AUTOSAR XML (schema 4-2-2)
package /STELLANTIS/EPT/ASWCs
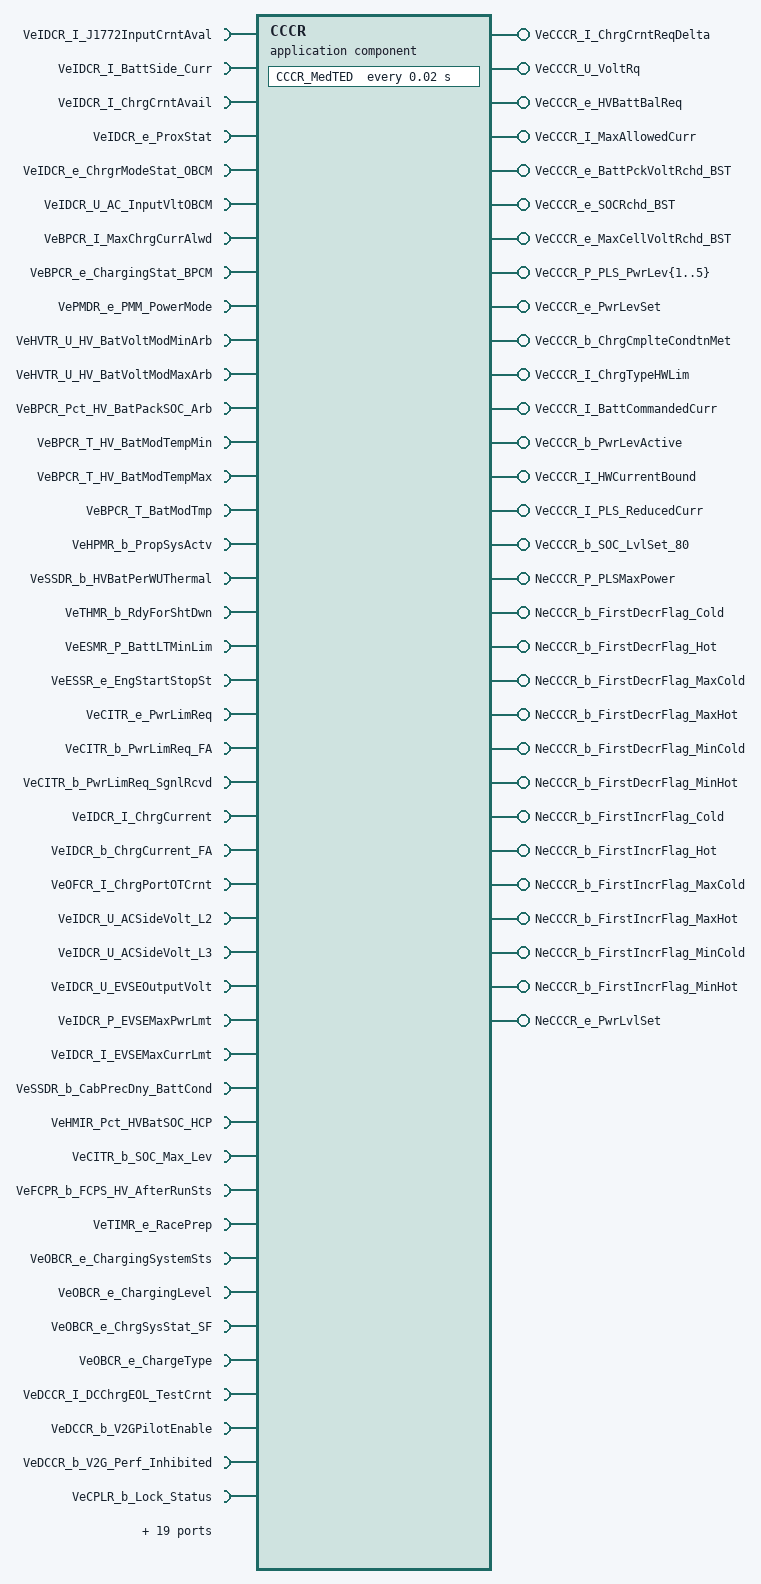
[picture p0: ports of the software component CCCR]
  application sw component type CCCR
    49 x require port:
      VeIDCR_I_J1772InputCrntAval: variation-point={short-label=vpVeIDCR_I_J1772InputCrntAval, sw-syscond=1}, nonqueued-receiver-com-spec{data-element=Value, init-value=0}, required-interface=VeIDCR_I_J1772InputCrntAval
      VeIDCR_I_BattSide_Curr: variation-point={short-label=vpVeIDCR_I_BattSide_Curr, sw-syscond=1}, nonqueued-receiver-com-spec{data-element=Value, init-value=0}, required-interface=VeIDCR_I_BattSide_Curr
      VeIDCR_I_ChrgCrntAvail: variation-point={short-label=vpVeIDCR_I_ChrgCrntAvail, sw-syscond=1}, nonqueued-receiver-com-spec{data-element=Value, init-value=0}, required-interface=VeIDCR_I_ChrgCrntAvail
      VeIDCR_e_ProxStat: variation-point={short-label=vpVeIDCR_e_ProxStat, sw-syscond=1}, nonqueued-receiver-com-spec{data-element=Value, init-value=CeOBCR_e_ProxLo_OBCM}, required-interface=VeIDCR_e_ProxStat
      VeIDCR_e_ChrgrModeStat_OBCM: variation-point={short-label=vpVeIDCR_e_ChrgrModeStat_OBCM, sw-syscond=1}, nonqueued-receiver-com-spec{data-element=Value, init-value=CeOBCR_e_Idle_OBCM}, required-interface=VeIDCR_e_ChrgrModeStat_OBCM
      VeIDCR_U_AC_InputVltOBCM: variation-point={short-label=vpVeIDCR_U_AC_InputVltOBCM, sw-syscond=1}, nonqueued-receiver-com-spec{data-element=Value, init-value=0}, required-interface=VeIDCR_U_AC_InputVltOBCM
      VeBPCR_I_MaxChrgCurrAlwd: variation-point={short-label=vpVeBPCR_I_MaxChrgCurrAlwd, sw-syscond=1}, nonqueued-receiver-com-spec{data-element=Value, init-value=0}, required-interface=VeBPCR_I_MaxChrgCurrAlwd
      VeBPCR_e_ChargingStat_BPCM: variation-point={short-label=vpVeBPCR_e_ChargingStat_BPCM, sw-syscond=1}, nonqueued-receiver-com-spec{data-element=Value, init-value=CeOBCR_e_BattNotReady}, required-interface=VeBPCR_e_ChargingStat_BPCM
      VePMDR_e_PMM_PowerMode: variation-point={short-label=vpVePMDR_e_PMM_PowerMode, sw-syscond=1}, nonqueued-receiver-com-spec{data-element=Value, init-value=CePMDR_e_PowerMode_Off}, required-interface=VePMDR_e_PMM_PowerMode
      VeHVTR_U_HV_BatVoltModMinArb: variation-point={short-label=vpVeHVTR_U_HV_BatVoltModMinArb, sw-syscond=1}, nonqueued-receiver-com-spec{data-element=Value, init-value=0}, required-interface=VeHVTR_U_HV_BatVoltModMinArb
      VeHVTR_U_HV_BatVoltModMaxArb: variation-point={short-label=vpVeHVTR_U_HV_BatVoltModMaxArb, sw-syscond=1}, nonqueued-receiver-com-spec{data-element=Value, init-value=0}, required-interface=VeHVTR_U_HV_BatVoltModMaxArb
      VeBPCR_Pct_HV_BatPackSOC_Arb: variation-point={short-label=vpVeBPCR_Pct_HV_BatPackSOC_Arb, sw-syscond=1}, nonqueued-receiver-com-spec{data-element=Value, init-value=0}, required-interface=VeBPCR_Pct_HV_BatPackSOC_Arb
      VeBPCR_T_HV_BatModTempMin: variation-point={short-label=vpVeBPCR_T_HV_BatModTempMin, sw-syscond=1}, nonqueued-receiver-com-spec{data-element=Value, init-value=0}, required-interface=VeBPCR_T_HV_BatModTempMin
      VeBPCR_T_HV_BatModTempMax: variation-point={short-label=vpVeBPCR_T_HV_BatModTempMax, sw-syscond=1}, nonqueued-receiver-com-spec{data-element=Value, init-value=0}, required-interface=VeBPCR_T_HV_BatModTempMax
      VeBPCR_T_BatModTmp: variation-point={short-label=vpVeBPCR_T_BatModTmp, sw-syscond=1}, nonqueued-receiver-com-spec{data-element=Value, init-value=0}, required-interface=VeBPCR_T_BatModTmp
      VeHPMR_b_PropSysActv: variation-point={short-label=vpVeHPMR_b_PropSysActv, sw-syscond=1}, nonqueued-receiver-com-spec{data-element=Value, init-value=0}, required-interface=VeHPMR_b_PropSysActv
      VeSSDR_b_HVBatPerWUThermal: variation-point={short-label=vpVeSSDR_b_HVBatPerWUThermal, sw-syscond=1}, nonqueued-receiver-com-spec{data-element=Value, init-value=0}, required-interface=VeSSDR_b_HVBatPerWUThermal
      VeTHMR_b_RdyForShtDwn: variation-point={short-label=vpVeTHMR_b_RdyForShtDwn, sw-syscond=1}, nonqueued-receiver-com-spec{data-element=Value, init-value=0}, required-interface=VeTHMR_b_RdyForShtDwn
      VeESMR_P_BattLTMinLim: variation-point={short-label=vpVeESMR_P_BattLTMinLim, sw-syscond=1}, nonqueued-receiver-com-spec{data-element=Value, init-value=0}, required-interface=VeESMR_P_BattLTMinLim
      VeESSR_e_EngStartStopSt: variation-point={short-label=vpVeESSR_e_EngStartStopSt, sw-syscond=1}, nonqueued-receiver-com-spec{data-element=Value, init-value=CeESSR_e_EngOff}, required-interface=VeESSR_e_EngStartStopSt
      VeCITR_e_PwrLimReq: variation-point={short-label=vpVeCITR_e_PwrLimReq, sw-syscond=1}, nonqueued-receiver-com-spec{data-element=Value, init-value=CeOBCR_e_PwrLimReq_SNA}, required-interface=VeCITR_e_PwrLimReq
      VeCITR_b_PwrLimReq_FA: variation-point={short-label=vpVeCITR_b_PwrLimReq_FA, sw-syscond=1}, nonqueued-receiver-com-spec{data-element=Value, init-value=0}, required-interface=VeCITR_b_PwrLimReq_FA
      VeCITR_b_PwrLimReq_SgnlRcvd: variation-point={short-label=vpVeCITR_b_PwrLimReq_SgnlRcvd, sw-syscond=1}, nonqueued-receiver-com-spec{data-element=Value, init-value=0}, required-interface=VeCITR_b_PwrLimReq_SgnlRcvd
      VeIDCR_I_ChrgCurrent: variation-point={short-label=vpVeIDCR_I_ChrgCurrent, sw-syscond=1}, nonqueued-receiver-com-spec{data-element=Value, init-value=0}, required-interface=VeIDCR_I_ChrgCurrent
      VeIDCR_b_ChrgCurrent_FA: variation-point={short-label=vpVeIDCR_b_ChrgCurrent_FA, sw-syscond=1}, nonqueued-receiver-com-spec{data-element=Value, init-value=0}, required-interface=VeIDCR_b_ChrgCurrent_FA
      VeOFCR_I_ChrgPortOTCrnt: variation-point={short-label=vpVeOFCR_I_ChrgPortOTCrnt, sw-syscond=1}, nonqueued-receiver-com-spec{data-element=Value, init-value=0}, required-interface=VeOFCR_I_ChrgPortOTCrnt
      VeIDCR_U_ACSideVolt_L2: variation-point={short-label=vpVeIDCR_U_ACSideVolt_L2, sw-syscond=1}, nonqueued-receiver-com-spec{data-element=Value, init-value=0}, required-interface=VeIDCR_U_ACSideVolt_L2
      VeIDCR_U_ACSideVolt_L3: variation-point={short-label=vpVeIDCR_U_ACSideVolt_L3, sw-syscond=1}, nonqueued-receiver-com-spec{data-element=Value, init-value=0}, required-interface=VeIDCR_U_ACSideVolt_L3
      VeIDCR_U_EVSEOutputVolt: variation-point={short-label=vpVeIDCR_U_EVSEOutputVolt, sw-syscond=1}, nonqueued-receiver-com-spec{data-element=Value, init-value=0}, required-interface=VeIDCR_U_EVSEOutputVolt
      VeIDCR_P_EVSEMaxPwrLmt: variation-point={short-label=vpVeIDCR_P_EVSEMaxPwrLmt, sw-syscond=1}, nonqueued-receiver-com-spec{data-element=Value, init-value=0}, required-interface=VeIDCR_P_EVSEMaxPwrLmt
      VeIDCR_I_EVSEMaxCurrLmt: variation-point={short-label=vpVeIDCR_I_EVSEMaxCurrLmt, sw-syscond=1}, nonqueued-receiver-com-spec{data-element=Value, init-value=0}, required-interface=VeIDCR_I_EVSEMaxCurrLmt
      VeSSDR_b_CabPrecDny_BattCond: variation-point={short-label=vpVeSSDR_b_CabPrecDny_BattCond, sw-syscond=1}, nonqueued-receiver-com-spec{data-element=Value, init-value=0}, required-interface=VeSSDR_b_CabPrecDny_BattCond
      VeHMIR_Pct_HVBatSOC_HCP: variation-point={short-label=vpVeHMIR_Pct_HVBatSOC_HCP, sw-syscond=1}, nonqueued-receiver-com-spec{data-element=Value, init-value=0}, required-interface=VeHMIR_Pct_HVBatSOC_HCP
      VeCITR_b_SOC_Max_Lev: variation-point={short-label=vpVeCITR_b_SOC_Max_Lev, sw-syscond=1}, nonqueued-receiver-com-spec{data-element=Value, init-value=0}, required-interface=VeCITR_b_SOC_Max_Lev
      VeFCPR_b_FCPS_HV_AfterRunSts: variation-point={short-label=vpVeFCPR_b_FCPS_HV_AfterRunSts, sw-syscond=1}, nonqueued-receiver-com-spec{data-element=Value, init-value=0}, required-interface=VeFCPR_b_FCPS_HV_AfterRunSts
      VeTIMR_e_RacePrep: variation-point={short-label=vpVeTIMR_e_RacePrep, sw-syscond=1}, nonqueued-receiver-com-spec{data-element=Value, init-value=CeTIMR_e_RacePrep_Off}, required-interface=VeTIMR_e_RacePrep
      VeOBCR_e_ChargingSystemSts: variation-point={short-label=vpVeOBCR_e_ChargingSystemSts, sw-syscond=1}, nonqueued-receiver-com-spec{data-element=Value, init-value=CeOBCR_e_NotCharging}, required-interface=VeOBCR_e_ChargingSystemSts
      VeOBCR_e_ChargingLevel: variation-point={short-label=vpVeOBCR_e_ChargingLevel, sw-syscond=1}, nonqueued-receiver-com-spec{data-element=Value, init-value=CeOBCR_e_ChargingLvlDefault}, required-interface=VeOBCR_e_ChargingLevel
      VeOBCR_e_ChrgSysStat_SF: variation-point={short-label=vpVeOBCR_e_ChrgSysStat_SF, sw-syscond=1}, nonqueued-receiver-com-spec{data-element=Value, init-value=CeOBCR_e_PowerUp}, required-interface=VeOBCR_e_ChrgSysStat_SF
      VeOBCR_e_ChargeType: variation-point={short-label=vpVeOBCR_e_ChargeType, sw-syscond=1}, nonqueued-receiver-com-spec{data-element=Value, init-value=CeOBCR_e_AC}, required-interface=VeOBCR_e_ChargeType
      VeDCCR_I_DCChrgEOL_TestCrnt: variation-point={short-label=vpVeDCCR_I_DCChrgEOL_TestCrnt, sw-syscond=1}, nonqueued-receiver-com-spec{data-element=Value, init-value=0}, required-interface=VeDCCR_I_DCChrgEOL_TestCrnt
      VeDCCR_b_V2GPilotEnable: variation-point={short-label=vpVeDCCR_b_V2GPilotEnable, sw-syscond=1}, nonqueued-receiver-com-spec{data-element=Value, init-value=0}, required-interface=VeDCCR_b_V2GPilotEnable
      VeDCCR_b_V2G_Perf_Inhibited: variation-point={short-label=vpVeDCCR_b_V2G_Perf_Inhibited, sw-syscond=1}, nonqueued-receiver-com-spec{data-element=Value, init-value=0}, required-interface=VeDCCR_b_V2G_Perf_Inhibited
      VeCPLR_b_Lock_Status: variation-point={short-label=vpVeCPLR_b_Lock_Status, sw-syscond=1}, nonqueued-receiver-com-spec{data-element=Value, init-value=0}, required-interface=VeCPLR_b_Lock_Status
      VeOBCR_b_PluggedIn: variation-point={short-label=vpVeOBCR_b_PluggedIn, sw-syscond=1}, nonqueued-receiver-com-spec{data-element=Value, init-value=0}, required-interface=VeOBCR_b_PluggedIn
      VeHVTR_I_StringsCurrFdbk: variation-point={short-label=vpVeHVTR_I_StringsCurrFdbk, sw-syscond=1}, nonqueued-receiver-com-spec{data-element=Value, init-value=0}, required-interface=VeHVTR_I_StringsCurrFdbk
      VeHVTR_U_HvBattVolt_Max: variation-point={short-label=vpVeHVTR_U_HvBattVolt_Max, sw-syscond=1}, nonqueued-receiver-com-spec{data-element=Value, init-value=0}, required-interface=VeHVTR_U_HvBattVolt_Max
      VeOBCR_b_EnblDsblProxPlg: variation-point={short-label=vpVeOBCR_b_EnblDsblProxPlg, sw-syscond=1}, nonqueued-receiver-com-spec{data-element=Value, init-value=0}, required-interface=VeOBCR_b_EnblDsblProxPlg
      VeTHMR_I_ChargeCurrentLim: variation-point={short-label=vpVeTHMR_I_ChargeCurrentLim, sw-syscond=1}, nonqueued-receiver-com-spec{data-element=Value, init-value=0}, required-interface=VeTHMR_I_ChargeCurrentLim
    20 x provide port:
      VeCCCR_I_ChrgCrntReqDelta: nonqueued-sender-com-spec{data-element=Value, init-value=0}, provided-interface=VeCCCR_I_ChrgCrntReqDelta
      VeCCCR_U_VoltRq: nonqueued-sender-com-spec{data-element=Value, init-value=0}, provided-interface=VeCCCR_U_VoltRq
      VeCCCR_e_HVBattBalReq: nonqueued-sender-com-spec{data-element=Value, init-value=CeOBCR_e_NoRequest}, provided-interface=VeCCCR_e_HVBattBalReq
      VeCCCR_I_MaxAllowedCurr: nonqueued-sender-com-spec{data-element=Value, init-value=0}, provided-interface=VeCCCR_I_MaxAllowedCurr
      VeCCCR_e_BattPckVoltRchd_BST: nonqueued-sender-com-spec{data-element=Value, init-value=CeOBCR_e_BattPckVolt_NotReached}, provided-interface=VeCCCR_e_BattPckVoltRchd_BST
      VeCCCR_e_SOCRchd_BST: nonqueued-sender-com-spec{data-element=Value, init-value=CeOBCR_e_SOC_NotReached}, provided-interface=VeCCCR_e_SOCRchd_BST
      VeCCCR_e_MaxCellVoltRchd_BST: nonqueued-sender-com-spec{data-element=Value, init-value=CeOBCR_e_MaxCellVolt_NotReached}, provided-interface=VeCCCR_e_MaxCellVoltRchd_BST
      VeCCCR_P_PLS_PwrLev{1..5}: nonqueued-sender-com-spec{data-element=Value, init-value=0}, provided-interface=VeCCCR_P_PLS_PwrLev{1..5}
      VeCCCR_e_PwrLevSet: nonqueued-sender-com-spec{data-element=Value, init-value=CeOBCR_e_PwrLimReq_SNA}, provided-interface=VeCCCR_e_PwrLevSet
      VeCCCR_b_ChrgCmplteCondtnMet: nonqueued-sender-com-spec{data-element=Value, init-value=0}, provided-interface=VeCCCR_b_ChrgCmplteCondtnMet
      VeCCCR_I_ChrgTypeHWLim: nonqueued-sender-com-spec{data-element=Value, init-value=0}, provided-interface=VeCCCR_I_ChrgTypeHWLim
      VeCCCR_I_BattCommandedCurr: nonqueued-sender-com-spec{data-element=Value, init-value=0}, provided-interface=VeCCCR_I_BattCommandedCurr
      VeCCCR_b_PwrLevActive: nonqueued-sender-com-spec{data-element=Value, init-value=0}, provided-interface=VeCCCR_b_PwrLevActive
      VeCCCR_I_HWCurrentBound: nonqueued-sender-com-spec{data-element=Value, init-value=0}, provided-interface=VeCCCR_I_HWCurrentBound
      VeCCCR_I_PLS_ReducedCurr: nonqueued-sender-com-spec{data-element=Value, init-value=0}, provided-interface=VeCCCR_I_PLS_ReducedCurr
      VeCCCR_b_SOC_LvlSet_80: nonqueued-sender-com-spec{data-element=Value, init-value=0}, provided-interface=VeCCCR_b_SOC_LvlSet_80
    14 x require port:
      NeCCCR_P_PLSMaxPower_Rx: variation-point={short-label=vpNeCCCR_P_PLSMaxPower_Rx, sw-syscond=1}, nv-require-com-spec{init-value=0, variable=NeCCCR_P_PLSMaxPower}, required-interface=NeCCCR_P_PLSMaxPower
      NeCCCR_e_PwrLvlSet_Rx: variation-point={short-label=vpNeCCCR_e_PwrLvlSet_Rx, sw-syscond=1}, nv-require-com-spec{init-value=CeOBCR_e_PwrLimReq_SNA, variable=NeCCCR_e_PwrLvlSet}, required-interface=NeCCCR_e_PwrLvlSet
      NeCCCR_b_FirstDecrFlag_Cold_Rx: variation-point={short-label=vpNeCCCR_b_FirstDecrFlag_Cold_Rx, sw-syscond=1}, nv-require-com-spec{init-value=0, variable=NeCCCR_b_FirstDecrFlag_Cold}, required-interface=NeCCCR_b_FirstDecrFlag_Cold
      NeCCCR_b_FirstDecrFlag_Hot_Rx: variation-point={short-label=vpNeCCCR_b_FirstDecrFlag_Hot_Rx, sw-syscond=1}, nv-require-com-spec{init-value=0, variable=NeCCCR_b_FirstDecrFlag_Hot}, required-interface=NeCCCR_b_FirstDecrFlag_Hot
      NeCCCR_b_FirstDecrFlag_MaxCold_Rx: variation-point={short-label=vpNeCCCR_b_FirstDecrFlag_MaxCold_Rx, sw-syscond=1}, nv-require-com-spec{init-value=0, variable=NeCCCR_b_FirstDecrFlag_MaxCold}, required-interface=NeCCCR_b_FirstDecrFlag_MaxCold
      NeCCCR_b_FirstDecrFlag_MaxHot_Rx: variation-point={short-label=vpNeCCCR_b_FirstDecrFlag_MaxHot_Rx, sw-syscond=1}, nv-require-com-spec{init-value=0, variable=NeCCCR_b_FirstDecrFlag_MaxHot}, required-interface=NeCCCR_b_FirstDecrFlag_MaxHot
      NeCCCR_b_FirstDecrFlag_MinCold_Rx: variation-point={short-label=vpNeCCCR_b_FirstDecrFlag_MinCold_Rx, sw-syscond=1}, nv-require-com-spec{init-value=0, variable=NeCCCR_b_FirstDecrFlag_MinCold}, required-interface=NeCCCR_b_FirstDecrFlag_MinCold
      NeCCCR_b_FirstDecrFlag_MinHot_Rx: variation-point={short-label=vpNeCCCR_b_FirstDecrFlag_MinHot_Rx, sw-syscond=1}, nv-require-com-spec{init-value=0, variable=NeCCCR_b_FirstDecrFlag_MinHot}, required-interface=NeCCCR_b_FirstDecrFlag_MinHot
      NeCCCR_b_FirstIncrFlag_Cold_Rx: variation-point={short-label=vpNeCCCR_b_FirstIncrFlag_Cold_Rx, sw-syscond=1}, nv-require-com-spec{init-value=0, variable=NeCCCR_b_FirstIncrFlag_Cold}, required-interface=NeCCCR_b_FirstIncrFlag_Cold
      NeCCCR_b_FirstIncrFlag_Hot_Rx: variation-point={short-label=vpNeCCCR_b_FirstIncrFlag_Hot_Rx, sw-syscond=1}, nv-require-com-spec{init-value=0, variable=NeCCCR_b_FirstIncrFlag_Hot}, required-interface=NeCCCR_b_FirstIncrFlag_Hot
      NeCCCR_b_FirstIncrFlag_MaxCold_Rx: variation-point={short-label=vpNeCCCR_b_FirstIncrFlag_MaxCold_Rx, sw-syscond=1}, nv-require-com-spec{init-value=0, variable=NeCCCR_b_FirstIncrFlag_MaxCold}, required-interface=NeCCCR_b_FirstIncrFlag_MaxCold
      NeCCCR_b_FirstIncrFlag_MaxHot_Rx: variation-point={short-label=vpNeCCCR_b_FirstIncrFlag_MaxHot_Rx, sw-syscond=1}, nv-require-com-spec{init-value=0, variable=NeCCCR_b_FirstIncrFlag_MaxHot}, required-interface=NeCCCR_b_FirstIncrFlag_MaxHot
      NeCCCR_b_FirstIncrFlag_MinCold_Rx: variation-point={short-label=vpNeCCCR_b_FirstIncrFlag_MinCold_Rx, sw-syscond=1}, nv-require-com-spec{init-value=0, variable=NeCCCR_b_FirstIncrFlag_MinCold}, required-interface=NeCCCR_b_FirstIncrFlag_MinCold
      NeCCCR_b_FirstIncrFlag_MinHot_Rx: variation-point={short-label=vpNeCCCR_b_FirstIncrFlag_MinHot_Rx, sw-syscond=1}, nv-require-com-spec{init-value=0, variable=NeCCCR_b_FirstIncrFlag_MinHot}, required-interface=NeCCCR_b_FirstIncrFlag_MinHot
    14 x provide port:
      NeCCCR_P_PLSMaxPower: variation-point={short-label=vpNeCCCR_P_PLSMaxPower, sw-syscond=1}, nv-provide-com-spec{ram-block-init-value=0, variable=NeCCCR_P_PLSMaxPower}, provided-interface=NeCCCR_P_PLSMaxPower
      NeCCCR_b_FirstDecrFlag_Cold: variation-point={short-label=vpNeCCCR_b_FirstDecrFlag_Cold, sw-syscond=1}, nv-provide-com-spec{ram-block-init-value=0, variable=NeCCCR_b_FirstDecrFlag_Cold}, provided-interface=NeCCCR_b_FirstDecrFlag_Cold
      NeCCCR_b_FirstDecrFlag_Hot: variation-point={short-label=vpNeCCCR_b_FirstDecrFlag_Hot, sw-syscond=1}, nv-provide-com-spec{ram-block-init-value=0, variable=NeCCCR_b_FirstDecrFlag_Hot}, provided-interface=NeCCCR_b_FirstDecrFlag_Hot
      NeCCCR_b_FirstDecrFlag_MaxCold: variation-point={short-label=vpNeCCCR_b_FirstDecrFlag_MaxCold, sw-syscond=1}, nv-provide-com-spec{ram-block-init-value=0, variable=NeCCCR_b_FirstDecrFlag_MaxCold}, provided-interface=NeCCCR_b_FirstDecrFlag_MaxCold
      NeCCCR_b_FirstDecrFlag_MaxHot: variation-point={short-label=vpNeCCCR_b_FirstDecrFlag_MaxHot, sw-syscond=1}, nv-provide-com-spec{ram-block-init-value=0, variable=NeCCCR_b_FirstDecrFlag_MaxHot}, provided-interface=NeCCCR_b_FirstDecrFlag_MaxHot
      NeCCCR_b_FirstDecrFlag_MinCold: variation-point={short-label=vpNeCCCR_b_FirstDecrFlag_MinCold, sw-syscond=1}, nv-provide-com-spec{ram-block-init-value=0, variable=NeCCCR_b_FirstDecrFlag_MinCold}, provided-interface=NeCCCR_b_FirstDecrFlag_MinCold
      NeCCCR_b_FirstDecrFlag_MinHot: variation-point={short-label=vpNeCCCR_b_FirstDecrFlag_MinHot, sw-syscond=1}, nv-provide-com-spec{ram-block-init-value=0, variable=NeCCCR_b_FirstDecrFlag_MinHot}, provided-interface=NeCCCR_b_FirstDecrFlag_MinHot
      NeCCCR_b_FirstIncrFlag_Cold: variation-point={short-label=vpNeCCCR_b_FirstIncrFlag_Cold, sw-syscond=1}, nv-provide-com-spec{ram-block-init-value=0, variable=NeCCCR_b_FirstIncrFlag_Cold}, provided-interface=NeCCCR_b_FirstIncrFlag_Cold
      NeCCCR_b_FirstIncrFlag_Hot: variation-point={short-label=vpNeCCCR_b_FirstIncrFlag_Hot, sw-syscond=1}, nv-provide-com-spec{ram-block-init-value=0, variable=NeCCCR_b_FirstIncrFlag_Hot}, provided-interface=NeCCCR_b_FirstIncrFlag_Hot
      NeCCCR_b_FirstIncrFlag_MaxCold: variation-point={short-label=vpNeCCCR_b_FirstIncrFlag_MaxCold, sw-syscond=1}, nv-provide-com-spec{ram-block-init-value=0, variable=NeCCCR_b_FirstIncrFlag_MaxCold}, provided-interface=NeCCCR_b_FirstIncrFlag_MaxCold
      NeCCCR_b_FirstIncrFlag_MaxHot: variation-point={short-label=vpNeCCCR_b_FirstIncrFlag_MaxHot, sw-syscond=1}, nv-provide-com-spec{ram-block-init-value=0, variable=NeCCCR_b_FirstIncrFlag_MaxHot}, provided-interface=NeCCCR_b_FirstIncrFlag_MaxHot
      NeCCCR_b_FirstIncrFlag_MinCold: variation-point={short-label=vpNeCCCR_b_FirstIncrFlag_MinCold, sw-syscond=1}, nv-provide-com-spec{ram-block-init-value=0, variable=NeCCCR_b_FirstIncrFlag_MinCold}, provided-interface=NeCCCR_b_FirstIncrFlag_MinCold
      NeCCCR_b_FirstIncrFlag_MinHot: variation-point={short-label=vpNeCCCR_b_FirstIncrFlag_MinHot, sw-syscond=1}, nv-provide-com-spec{ram-block-init-value=0, variable=NeCCCR_b_FirstIncrFlag_MinHot}, provided-interface=NeCCCR_b_FirstIncrFlag_MinHot
      NeCCCR_e_PwrLvlSet: variation-point={short-label=vpNeCCCR_e_PwrLvlSet, sw-syscond=1}, nv-provide-com-spec{ram-block-init-value=CeOBCR_e_PwrLimReq_SNA, variable=NeCCCR_e_PwrLvlSet}, provided-interface=NeCCCR_e_PwrLvlSet
    behavior IB_CCCR: data-type-mapping=msADTtoIDTMapping, handle-termination-and-restart=NO-SUPPORT, included-data-type-set=data-type=TeOBCR_e_OB_ChrgPwrLimID
      timing event Event_MedTED: start-on-event=CCCR_MedTED, period=0.02
      init event Event_CCCR_ac_Init: start-on-event=CCCR_ac_Init
      init event Event_PwrOn: start-on-event=CCCR_PwrOn
      init event Event_PwrOff: start-on-event=CCCR_PwrOff
      4 x runnable:
        CCCR_ac_Init
          data-send-points:
            6 x access:
              OUT_VeCCCR_e_HVBattBalReq_Value: accessed-variable=VeCCCR_e_HVBattBalReq.Value
              OUT_VeCCCR_e_BattPckVoltRchd_BST_Value: accessed-variable=VeCCCR_e_BattPckVoltRchd_BST.Value
              OUT_VeCCCR_e_SOCRchd_BST_Value: accessed-variable=VeCCCR_e_SOCRchd_BST.Value
              OUT_VeCCCR_e_MaxCellVoltRchd_BST_Value: accessed-variable=VeCCCR_e_MaxCellVoltRchd_BST.Value
              OUT_VeCCCR_e_PwrLevSet_Value: accessed-variable=VeCCCR_e_PwrLevSet.Value
              OUT_NeCCCR_e_PwrLvlSet_NeCCCR_e_PwrLvlSet: accessed-variable=NeCCCR_e_PwrLvlSet.NeCCCR_e_PwrLvlSet, variation-point={short-label=vpOUT_NeCCCR_e_PwrLvlSet_NeCCCR_e_PwrLvlSet, sw-syscond=1}
        CCCR_PwrOn
          data-receive-point-by-arguments:
            14 x access:
              IN_NeCCCR_P_PLSMaxPower_Rx_NeCCCR_P_PLSMaxPower: accessed-variable=NeCCCR_P_PLSMaxPower_Rx.NeCCCR_P_PLSMaxPower, variation-point={short-label=vpIN_NeCCCR_P_PLSMaxPower_Rx_NeCCCR_P_PLSMaxPower, sw-syscond=1}
              IN_NeCCCR_b_FirstDecrFlag_Cold_Rx_NeCCCR_b_FirstDecrFlag_Cold: accessed-variable=NeCCCR_b_FirstDecrFlag_Cold_Rx.NeCCCR_b_FirstDecrFlag_Cold, variation-point={short-label=vpIN_NeCCCR_b_FirstDecrFlag_Cold_Rx_NeCCCR_b_FirstDecrFlag_Cold, sw-syscond=1}
              IN_NeCCCR_b_FirstDecrFlag_Hot_Rx_NeCCCR_b_FirstDecrFlag_Hot: accessed-variable=NeCCCR_b_FirstDecrFlag_Hot_Rx.NeCCCR_b_FirstDecrFlag_Hot, variation-point={short-label=vpIN_NeCCCR_b_FirstDecrFlag_Hot_Rx_NeCCCR_b_FirstDecrFlag_Hot, sw-syscond=1}
              IN_NeCCCR_b_FirstDecrFlag_MaxCold_Rx_NeCCCR_b_FirstDecrFlag_MaxCold: accessed-variable=NeCCCR_b_FirstDecrFlag_MaxCold_Rx.NeCCCR_b_FirstDecrFlag_MaxCold, variation-point={short-label=vpIN_NeCCCR_b_FirstDecrFlag_MaxCold_Rx_NeCCCR_b_FirstDecrFlag_MaxCold, sw-syscond=1}
              IN_NeCCCR_b_FirstDecrFlag_MaxHot_Rx_NeCCCR_b_FirstDecrFlag_MaxHot: accessed-variable=NeCCCR_b_FirstDecrFlag_MaxHot_Rx.NeCCCR_b_FirstDecrFlag_MaxHot, variation-point={short-label=vpIN_NeCCCR_b_FirstDecrFlag_MaxHot_Rx_NeCCCR_b_FirstDecrFlag_MaxHot, sw-syscond=1}
              IN_NeCCCR_b_FirstDecrFlag_MinCold_Rx_NeCCCR_b_FirstDecrFlag_MinCold: accessed-variable=NeCCCR_b_FirstDecrFlag_MinCold_Rx.NeCCCR_b_FirstDecrFlag_MinCold, variation-point={short-label=vpIN_NeCCCR_b_FirstDecrFlag_MinCold_Rx_NeCCCR_b_FirstDecrFlag_MinCold, sw-syscond=1}
              IN_NeCCCR_b_FirstDecrFlag_MinHot_Rx_NeCCCR_b_FirstDecrFlag_MinHot: accessed-variable=NeCCCR_b_FirstDecrFlag_MinHot_Rx.NeCCCR_b_FirstDecrFlag_MinHot, variation-point={short-label=vpIN_NeCCCR_b_FirstDecrFlag_MinHot_Rx_NeCCCR_b_FirstDecrFlag_MinHot, sw-syscond=1}
              IN_NeCCCR_b_FirstIncrFlag_Cold_Rx_NeCCCR_b_FirstIncrFlag_Cold: accessed-variable=NeCCCR_b_FirstIncrFlag_Cold_Rx.NeCCCR_b_FirstIncrFlag_Cold, variation-point={short-label=vpIN_NeCCCR_b_FirstIncrFlag_Cold_Rx_NeCCCR_b_FirstIncrFlag_Cold, sw-syscond=1}
              IN_NeCCCR_b_FirstIncrFlag_Hot_Rx_NeCCCR_b_FirstIncrFlag_Hot: accessed-variable=NeCCCR_b_FirstIncrFlag_Hot_Rx.NeCCCR_b_FirstIncrFlag_Hot, variation-point={short-label=vpIN_NeCCCR_b_FirstIncrFlag_Hot_Rx_NeCCCR_b_FirstIncrFlag_Hot, sw-syscond=1}
              IN_NeCCCR_b_FirstIncrFlag_MaxCold_Rx_NeCCCR_b_FirstIncrFlag_MaxCold: accessed-variable=NeCCCR_b_FirstIncrFlag_MaxCold_Rx.NeCCCR_b_FirstIncrFlag_MaxCold, variation-point={short-label=vpIN_NeCCCR_b_FirstIncrFlag_MaxCold_Rx_NeCCCR_b_FirstIncrFlag_MaxCold, sw-syscond=1}
              IN_NeCCCR_b_FirstIncrFlag_MaxHot_Rx_NeCCCR_b_FirstIncrFlag_MaxHot: accessed-variable=NeCCCR_b_FirstIncrFlag_MaxHot_Rx.NeCCCR_b_FirstIncrFlag_MaxHot, variation-point={short-label=vpIN_NeCCCR_b_FirstIncrFlag_MaxHot_Rx_NeCCCR_b_FirstIncrFlag_MaxHot, sw-syscond=1}
              IN_NeCCCR_b_FirstIncrFlag_MinCold_Rx_NeCCCR_b_FirstIncrFlag_MinCold: accessed-variable=NeCCCR_b_FirstIncrFlag_MinCold_Rx.NeCCCR_b_FirstIncrFlag_MinCold, variation-point={short-label=vpIN_NeCCCR_b_FirstIncrFlag_MinCold_Rx_NeCCCR_b_FirstIncrFlag_MinCold, sw-syscond=1}
              IN_NeCCCR_b_FirstIncrFlag_MinHot_Rx_NeCCCR_b_FirstIncrFlag_MinHot: accessed-variable=NeCCCR_b_FirstIncrFlag_MinHot_Rx.NeCCCR_b_FirstIncrFlag_MinHot, variation-point={short-label=vpIN_NeCCCR_b_FirstIncrFlag_MinHot_Rx_NeCCCR_b_FirstIncrFlag_MinHot, sw-syscond=1}
              IN_NeCCCR_e_PwrLvlSet_Rx_NeCCCR_e_PwrLvlSet: accessed-variable=NeCCCR_e_PwrLvlSet_Rx.NeCCCR_e_PwrLvlSet, variation-point={short-label=vpIN_NeCCCR_e_PwrLvlSet_Rx_NeCCCR_e_PwrLvlSet, sw-syscond=1}
          data-send-points:
            20 x access:
              OUT_VeCCCR_I_ChrgCrntReqDelta_Value: accessed-variable=VeCCCR_I_ChrgCrntReqDelta.Value
              OUT_VeCCCR_U_VoltRq_Value: accessed-variable=VeCCCR_U_VoltRq.Value
              OUT_VeCCCR_e_HVBattBalReq_Value: accessed-variable=VeCCCR_e_HVBattBalReq.Value
              OUT_VeCCCR_I_MaxAllowedCurr_Value: accessed-variable=VeCCCR_I_MaxAllowedCurr.Value
              OUT_VeCCCR_e_BattPckVoltRchd_BST_Value: accessed-variable=VeCCCR_e_BattPckVoltRchd_BST.Value
              OUT_VeCCCR_e_SOCRchd_BST_Value: accessed-variable=VeCCCR_e_SOCRchd_BST.Value
              OUT_VeCCCR_e_MaxCellVoltRchd_BST_Value: accessed-variable=VeCCCR_e_MaxCellVoltRchd_BST.Value
              OUT_VeCCCR_P_PLS_PwrLev{1..5}_Value: accessed-variable=VeCCCR_P_PLS_PwrLev{1..5}.Value
              OUT_VeCCCR_e_PwrLevSet_Value: accessed-variable=VeCCCR_e_PwrLevSet.Value
              OUT_VeCCCR_b_ChrgCmplteCondtnMet_Value: accessed-variable=VeCCCR_b_ChrgCmplteCondtnMet.Value
              OUT_VeCCCR_I_ChrgTypeHWLim_Value: accessed-variable=VeCCCR_I_ChrgTypeHWLim.Value
              OUT_VeCCCR_I_BattCommandedCurr_Value: accessed-variable=VeCCCR_I_BattCommandedCurr.Value
              OUT_VeCCCR_b_PwrLevActive_Value: accessed-variable=VeCCCR_b_PwrLevActive.Value
              OUT_VeCCCR_I_HWCurrentBound_Value: accessed-variable=VeCCCR_I_HWCurrentBound.Value
              OUT_VeCCCR_I_PLS_ReducedCurr_Value: accessed-variable=VeCCCR_I_PLS_ReducedCurr.Value
              OUT_VeCCCR_b_SOC_LvlSet_80_Value: accessed-variable=VeCCCR_b_SOC_LvlSet_80.Value
        CCCR_MedTED: variation-point={short-label=vpCCCR_MedTED, sw-syscond=1}
          data-receive-point-by-arguments:
            49 x access:
              IN_VeBPCR_I_MaxChrgCurrAlwd_Value: accessed-variable=VeBPCR_I_MaxChrgCurrAlwd.Value, variation-point={short-label=vpIN_VeBPCR_I_MaxChrgCurrAlwd_Value, sw-syscond=1}
              IN_VeBPCR_Pct_HV_BatPackSOC_Arb_Value: accessed-variable=VeBPCR_Pct_HV_BatPackSOC_Arb.Value, variation-point={short-label=vpIN_VeBPCR_Pct_HV_BatPackSOC_Arb_Value, sw-syscond=1}
              IN_VeBPCR_T_BatModTmp_Value: accessed-variable=VeBPCR_T_BatModTmp.Value, variation-point={short-label=vpIN_VeBPCR_T_BatModTmp_Value, sw-syscond=1}
              IN_VeBPCR_T_HV_BatModTempMax_Value: accessed-variable=VeBPCR_T_HV_BatModTempMax.Value, variation-point={short-label=vpIN_VeBPCR_T_HV_BatModTempMax_Value, sw-syscond=1}
              IN_VeBPCR_T_HV_BatModTempMin_Value: accessed-variable=VeBPCR_T_HV_BatModTempMin.Value, variation-point={short-label=vpIN_VeBPCR_T_HV_BatModTempMin_Value, sw-syscond=1}
              IN_VeBPCR_e_ChargingStat_BPCM_Value: accessed-variable=VeBPCR_e_ChargingStat_BPCM.Value, variation-point={short-label=vpIN_VeBPCR_e_ChargingStat_BPCM_Value, sw-syscond=1}
              IN_VeCITR_b_PwrLimReq_FA_Value: accessed-variable=VeCITR_b_PwrLimReq_FA.Value, variation-point={short-label=vpIN_VeCITR_b_PwrLimReq_FA_Value, sw-syscond=1}
              IN_VeCITR_b_PwrLimReq_SgnlRcvd_Value: accessed-variable=VeCITR_b_PwrLimReq_SgnlRcvd.Value, variation-point={short-label=vpIN_VeCITR_b_PwrLimReq_SgnlRcvd_Value, sw-syscond=1}
              IN_VeCITR_b_SOC_Max_Lev_Value: accessed-variable=VeCITR_b_SOC_Max_Lev.Value, variation-point={short-label=vpIN_VeCITR_b_SOC_Max_Lev_Value, sw-syscond=1}
              IN_VeCITR_e_PwrLimReq_Value: accessed-variable=VeCITR_e_PwrLimReq.Value, variation-point={short-label=vpIN_VeCITR_e_PwrLimReq_Value, sw-syscond=1}
              IN_VeCPLR_b_Lock_Status_Value: accessed-variable=VeCPLR_b_Lock_Status.Value, variation-point={short-label=vpIN_VeCPLR_b_Lock_Status_Value, sw-syscond=1}
              IN_VeDCCR_I_DCChrgEOL_TestCrnt_Value: accessed-variable=VeDCCR_I_DCChrgEOL_TestCrnt.Value, variation-point={short-label=vpIN_VeDCCR_I_DCChrgEOL_TestCrnt_Value, sw-syscond=1}
              IN_VeDCCR_b_V2GPilotEnable_Value: accessed-variable=VeDCCR_b_V2GPilotEnable.Value, variation-point={short-label=vpIN_VeDCCR_b_V2GPilotEnable_Value, sw-syscond=1}
              IN_VeDCCR_b_V2G_Perf_Inhibited_Value: accessed-variable=VeDCCR_b_V2G_Perf_Inhibited.Value, variation-point={short-label=vpIN_VeDCCR_b_V2G_Perf_Inhibited_Value, sw-syscond=1}
              IN_VeESMR_P_BattLTMinLim_Value: accessed-variable=VeESMR_P_BattLTMinLim.Value, variation-point={short-label=vpIN_VeESMR_P_BattLTMinLim_Value, sw-syscond=1}
              IN_VeESSR_e_EngStartStopSt_Value: accessed-variable=VeESSR_e_EngStartStopSt.Value, variation-point={short-label=vpIN_VeESSR_e_EngStartStopSt_Value, sw-syscond=1}
              IN_VeFCPR_b_FCPS_HV_AfterRunSts_Value: accessed-variable=VeFCPR_b_FCPS_HV_AfterRunSts.Value, variation-point={short-label=vpIN_VeFCPR_b_FCPS_HV_AfterRunSts_Value, sw-syscond=1}
              IN_VeHMIR_Pct_HVBatSOC_HCP_Value: accessed-variable=VeHMIR_Pct_HVBatSOC_HCP.Value, variation-point={short-label=vpIN_VeHMIR_Pct_HVBatSOC_HCP_Value, sw-syscond=1}
              IN_VeHPMR_b_PropSysActv_Value: accessed-variable=VeHPMR_b_PropSysActv.Value, variation-point={short-label=vpIN_VeHPMR_b_PropSysActv_Value, sw-syscond=1}
              IN_VeHVTR_I_StringsCurrFdbk_Value: accessed-variable=VeHVTR_I_StringsCurrFdbk.Value, variation-point={short-label=vpIN_VeHVTR_I_StringsCurrFdbk_Value, sw-syscond=1}
              IN_VeHVTR_U_HV_BatVoltModMaxArb_Value: accessed-variable=VeHVTR_U_HV_BatVoltModMaxArb.Value, variation-point={short-label=vpIN_VeHVTR_U_HV_BatVoltModMaxArb_Value, sw-syscond=1}
              IN_VeHVTR_U_HV_BatVoltModMinArb_Value: accessed-variable=VeHVTR_U_HV_BatVoltModMinArb.Value, variation-point={short-label=vpIN_VeHVTR_U_HV_BatVoltModMinArb_Value, sw-syscond=1}
              IN_VeHVTR_U_HvBattVolt_Max_Value: accessed-variable=VeHVTR_U_HvBattVolt_Max.Value, variation-point={short-label=vpIN_VeHVTR_U_HvBattVolt_Max_Value, sw-syscond=1}
              IN_VeIDCR_I_BattSide_Curr_Value: accessed-variable=VeIDCR_I_BattSide_Curr.Value, variation-point={short-label=vpIN_VeIDCR_I_BattSide_Curr_Value, sw-syscond=1}
              IN_VeIDCR_I_ChrgCrntAvail_Value: accessed-variable=VeIDCR_I_ChrgCrntAvail.Value, variation-point={short-label=vpIN_VeIDCR_I_ChrgCrntAvail_Value, sw-syscond=1}
              IN_VeIDCR_I_ChrgCurrent_Value: accessed-variable=VeIDCR_I_ChrgCurrent.Value, variation-point={short-label=vpIN_VeIDCR_I_ChrgCurrent_Value, sw-syscond=1}
              IN_VeIDCR_I_EVSEMaxCurrLmt_Value: accessed-variable=VeIDCR_I_EVSEMaxCurrLmt.Value, variation-point={short-label=vpIN_VeIDCR_I_EVSEMaxCurrLmt_Value, sw-syscond=1}
              IN_VeIDCR_I_J1772InputCrntAval_Value: accessed-variable=VeIDCR_I_J1772InputCrntAval.Value, variation-point={short-label=vpIN_VeIDCR_I_J1772InputCrntAval_Value, sw-syscond=1}
              IN_VeIDCR_P_EVSEMaxPwrLmt_Value: accessed-variable=VeIDCR_P_EVSEMaxPwrLmt.Value, variation-point={short-label=vpIN_VeIDCR_P_EVSEMaxPwrLmt_Value, sw-syscond=1}
              IN_VeIDCR_U_ACSideVolt_L2_Value: accessed-variable=VeIDCR_U_ACSideVolt_L2.Value, variation-point={short-label=vpIN_VeIDCR_U_ACSideVolt_L2_Value, sw-syscond=1}
              IN_VeIDCR_U_ACSideVolt_L3_Value: accessed-variable=VeIDCR_U_ACSideVolt_L3.Value, variation-point={short-label=vpIN_VeIDCR_U_ACSideVolt_L3_Value, sw-syscond=1}
              IN_VeIDCR_U_AC_InputVltOBCM_Value: accessed-variable=VeIDCR_U_AC_InputVltOBCM.Value, variation-point={short-label=vpIN_VeIDCR_U_AC_InputVltOBCM_Value, sw-syscond=1}
              IN_VeIDCR_U_EVSEOutputVolt_Value: accessed-variable=VeIDCR_U_EVSEOutputVolt.Value, variation-point={short-label=vpIN_VeIDCR_U_EVSEOutputVolt_Value, sw-syscond=1}
              IN_VeIDCR_b_ChrgCurrent_FA_Value: accessed-variable=VeIDCR_b_ChrgCurrent_FA.Value, variation-point={short-label=vpIN_VeIDCR_b_ChrgCurrent_FA_Value, sw-syscond=1}
              IN_VeIDCR_e_ChrgrModeStat_OBCM_Value: accessed-variable=VeIDCR_e_ChrgrModeStat_OBCM.Value, variation-point={short-label=vpIN_VeIDCR_e_ChrgrModeStat_OBCM_Value, sw-syscond=1}
              IN_VeIDCR_e_ProxStat_Value: accessed-variable=VeIDCR_e_ProxStat.Value, variation-point={short-label=vpIN_VeIDCR_e_ProxStat_Value, sw-syscond=1}
              IN_VeOBCR_b_EnblDsblProxPlg_Value: accessed-variable=VeOBCR_b_EnblDsblProxPlg.Value, variation-point={short-label=vpIN_VeOBCR_b_EnblDsblProxPlg_Value, sw-syscond=1}
              IN_VeOBCR_b_PluggedIn_Value: accessed-variable=VeOBCR_b_PluggedIn.Value, variation-point={short-label=vpIN_VeOBCR_b_PluggedIn_Value, sw-syscond=1}
              IN_VeOBCR_e_ChargeType_Value: accessed-variable=VeOBCR_e_ChargeType.Value, variation-point={short-label=vpIN_VeOBCR_e_ChargeType_Value, sw-syscond=1}
              IN_VeOBCR_e_ChargingLevel_Value: accessed-variable=VeOBCR_e_ChargingLevel.Value, variation-point={short-label=vpIN_VeOBCR_e_ChargingLevel_Value, sw-syscond=1}
              IN_VeOBCR_e_ChargingSystemSts_Value: accessed-variable=VeOBCR_e_ChargingSystemSts.Value, variation-point={short-label=vpIN_VeOBCR_e_ChargingSystemSts_Value, sw-syscond=1}
              IN_VeOBCR_e_ChrgSysStat_SF_Value: accessed-variable=VeOBCR_e_ChrgSysStat_SF.Value, variation-point={short-label=vpIN_VeOBCR_e_ChrgSysStat_SF_Value, sw-syscond=1}
              IN_VeOFCR_I_ChrgPortOTCrnt_Value: accessed-variable=VeOFCR_I_ChrgPortOTCrnt.Value, variation-point={short-label=vpIN_VeOFCR_I_ChrgPortOTCrnt_Value, sw-syscond=1}
              IN_VePMDR_e_PMM_PowerMode_Value: accessed-variable=VePMDR_e_PMM_PowerMode.Value, variation-point={short-label=vpIN_VePMDR_e_PMM_PowerMode_Value, sw-syscond=1}
              IN_VeSSDR_b_CabPrecDny_BattCond_Value: accessed-variable=VeSSDR_b_CabPrecDny_BattCond.Value, variation-point={short-label=vpIN_VeSSDR_b_CabPrecDny_BattCond_Value, sw-syscond=1}
              IN_VeSSDR_b_HVBatPerWUThermal_Value: accessed-variable=VeSSDR_b_HVBatPerWUThermal.Value, variation-point={short-label=vpIN_VeSSDR_b_HVBatPerWUThermal_Value, sw-syscond=1}
              IN_VeTHMR_I_ChargeCurrentLim_Value: accessed-variable=VeTHMR_I_ChargeCurrentLim.Value, variation-point={short-label=vpIN_VeTHMR_I_ChargeCurrentLim_Value, sw-syscond=1}
              IN_VeTHMR_b_RdyForShtDwn_Value: accessed-variable=VeTHMR_b_RdyForShtDwn.Value, variation-point={short-label=vpIN_VeTHMR_b_RdyForShtDwn_Value, sw-syscond=1}
              IN_VeTIMR_e_RacePrep_Value: accessed-variable=VeTIMR_e_RacePrep.Value, variation-point={short-label=vpIN_VeTIMR_e_RacePrep_Value, sw-syscond=1}
          data-send-points:
            20 x access:
              OUT_VeCCCR_I_ChrgCrntReqDelta_Value: accessed-variable=VeCCCR_I_ChrgCrntReqDelta.Value
              OUT_VeCCCR_U_VoltRq_Value: accessed-variable=VeCCCR_U_VoltRq.Value
              OUT_VeCCCR_e_HVBattBalReq_Value: accessed-variable=VeCCCR_e_HVBattBalReq.Value
              OUT_VeCCCR_I_MaxAllowedCurr_Value: accessed-variable=VeCCCR_I_MaxAllowedCurr.Value
              OUT_VeCCCR_e_BattPckVoltRchd_BST_Value: accessed-variable=VeCCCR_e_BattPckVoltRchd_BST.Value
              OUT_VeCCCR_e_SOCRchd_BST_Value: accessed-variable=VeCCCR_e_SOCRchd_BST.Value
              OUT_VeCCCR_e_MaxCellVoltRchd_BST_Value: accessed-variable=VeCCCR_e_MaxCellVoltRchd_BST.Value
              OUT_VeCCCR_P_PLS_PwrLev{1..5}_Value: accessed-variable=VeCCCR_P_PLS_PwrLev{1..5}.Value
              OUT_VeCCCR_e_PwrLevSet_Value: accessed-variable=VeCCCR_e_PwrLevSet.Value
              OUT_VeCCCR_b_ChrgCmplteCondtnMet_Value: accessed-variable=VeCCCR_b_ChrgCmplteCondtnMet.Value
              OUT_VeCCCR_I_ChrgTypeHWLim_Value: accessed-variable=VeCCCR_I_ChrgTypeHWLim.Value
              OUT_VeCCCR_I_BattCommandedCurr_Value: accessed-variable=VeCCCR_I_BattCommandedCurr.Value
              OUT_VeCCCR_b_PwrLevActive_Value: accessed-variable=VeCCCR_b_PwrLevActive.Value
              OUT_VeCCCR_I_HWCurrentBound_Value: accessed-variable=VeCCCR_I_HWCurrentBound.Value
              OUT_VeCCCR_I_PLS_ReducedCurr_Value: accessed-variable=VeCCCR_I_PLS_ReducedCurr.Value
              OUT_VeCCCR_b_SOC_LvlSet_80_Value: accessed-variable=VeCCCR_b_SOC_LvlSet_80.Value
        CCCR_PwrOff: variation-point={short-label=vpCCCR_PwrOff, sw-syscond=1}
          data-send-points:
            14 x access:
              OUT_NeCCCR_P_PLSMaxPower_NeCCCR_P_PLSMaxPower: accessed-variable=NeCCCR_P_PLSMaxPower.NeCCCR_P_PLSMaxPower, variation-point={short-label=vpOUT_NeCCCR_P_PLSMaxPower_NeCCCR_P_PLSMaxPower, sw-syscond=1}
              OUT_NeCCCR_b_FirstDecrFlag_Cold_NeCCCR_b_FirstDecrFlag_Cold: accessed-variable=NeCCCR_b_FirstDecrFlag_Cold.NeCCCR_b_FirstDecrFlag_Cold, variation-point={short-label=vpOUT_NeCCCR_b_FirstDecrFlag_Cold_NeCCCR_b_FirstDecrFlag_Cold, sw-syscond=1}
              OUT_NeCCCR_b_FirstDecrFlag_Hot_NeCCCR_b_FirstDecrFlag_Hot: accessed-variable=NeCCCR_b_FirstDecrFlag_Hot.NeCCCR_b_FirstDecrFlag_Hot, variation-point={short-label=vpOUT_NeCCCR_b_FirstDecrFlag_Hot_NeCCCR_b_FirstDecrFlag_Hot, sw-syscond=1}
              OUT_NeCCCR_b_FirstDecrFlag_MaxCold_NeCCCR_b_FirstDecrFlag_MaxCold: accessed-variable=NeCCCR_b_FirstDecrFlag_MaxCold.NeCCCR_b_FirstDecrFlag_MaxCold, variation-point={short-label=vpOUT_NeCCCR_b_FirstDecrFlag_MaxCold_NeCCCR_b_FirstDecrFlag_MaxCold, sw-syscond=1}
              OUT_NeCCCR_b_FirstDecrFlag_MaxHot_NeCCCR_b_FirstDecrFlag_MaxHot: accessed-variable=NeCCCR_b_FirstDecrFlag_MaxHot.NeCCCR_b_FirstDecrFlag_MaxHot, variation-point={short-label=vpOUT_NeCCCR_b_FirstDecrFlag_MaxHot_NeCCCR_b_FirstDecrFlag_MaxHot, sw-syscond=1}
              OUT_NeCCCR_b_FirstDecrFlag_MinCold_NeCCCR_b_FirstDecrFlag_MinCold: accessed-variable=NeCCCR_b_FirstDecrFlag_MinCold.NeCCCR_b_FirstDecrFlag_MinCold, variation-point={short-label=vpOUT_NeCCCR_b_FirstDecrFlag_MinCold_NeCCCR_b_FirstDecrFlag_MinCold, sw-syscond=1}
              OUT_NeCCCR_b_FirstDecrFlag_MinHot_NeCCCR_b_FirstDecrFlag_MinHot: accessed-variable=NeCCCR_b_FirstDecrFlag_MinHot.NeCCCR_b_FirstDecrFlag_MinHot, variation-point={short-label=vpOUT_NeCCCR_b_FirstDecrFlag_MinHot_NeCCCR_b_FirstDecrFlag_MinHot, sw-syscond=1}
              OUT_NeCCCR_b_FirstIncrFlag_Cold_NeCCCR_b_FirstIncrFlag_Cold: accessed-variable=NeCCCR_b_FirstIncrFlag_Cold.NeCCCR_b_FirstIncrFlag_Cold, variation-point={short-label=vpOUT_NeCCCR_b_FirstIncrFlag_Cold_NeCCCR_b_FirstIncrFlag_Cold, sw-syscond=1}
              OUT_NeCCCR_b_FirstIncrFlag_Hot_NeCCCR_b_FirstIncrFlag_Hot: accessed-variable=NeCCCR_b_FirstIncrFlag_Hot.NeCCCR_b_FirstIncrFlag_Hot, variation-point={short-label=vpOUT_NeCCCR_b_FirstIncrFlag_Hot_NeCCCR_b_FirstIncrFlag_Hot, sw-syscond=1}
              OUT_NeCCCR_b_FirstIncrFlag_MaxCold_NeCCCR_b_FirstIncrFlag_MaxCold: accessed-variable=NeCCCR_b_FirstIncrFlag_MaxCold.NeCCCR_b_FirstIncrFlag_MaxCold, variation-point={short-label=vpOUT_NeCCCR_b_FirstIncrFlag_MaxCold_NeCCCR_b_FirstIncrFlag_MaxCold, sw-syscond=1}
              OUT_NeCCCR_b_FirstIncrFlag_MaxHot_NeCCCR_b_FirstIncrFlag_MaxHot: accessed-variable=NeCCCR_b_FirstIncrFlag_MaxHot.NeCCCR_b_FirstIncrFlag_MaxHot, variation-point={short-label=vpOUT_NeCCCR_b_FirstIncrFlag_MaxHot_NeCCCR_b_FirstIncrFlag_MaxHot, sw-syscond=1}
              OUT_NeCCCR_b_FirstIncrFlag_MinCold_NeCCCR_b_FirstIncrFlag_MinCold: accessed-variable=NeCCCR_b_FirstIncrFlag_MinCold.NeCCCR_b_FirstIncrFlag_MinCold, variation-point={short-label=vpOUT_NeCCCR_b_FirstIncrFlag_MinCold_NeCCCR_b_FirstIncrFlag_MinCold, sw-syscond=1}
              OUT_NeCCCR_b_FirstIncrFlag_MinHot_NeCCCR_b_FirstIncrFlag_MinHot: accessed-variable=NeCCCR_b_FirstIncrFlag_MinHot.NeCCCR_b_FirstIncrFlag_MinHot, variation-point={short-label=vpOUT_NeCCCR_b_FirstIncrFlag_MinHot_NeCCCR_b_FirstIncrFlag_MinHot, sw-syscond=1}
              OUT_NeCCCR_e_PwrLvlSet_NeCCCR_e_PwrLvlSet: accessed-variable=NeCCCR_e_PwrLvlSet.NeCCCR_e_PwrLvlSet, variation-point={short-label=vpOUT_NeCCCR_e_PwrLvlSet_NeCCCR_e_PwrLvlSet, sw-syscond=1}
      variation point proxy Variant_CCCR_FUNC: category=CONDITION, condition-access=1
